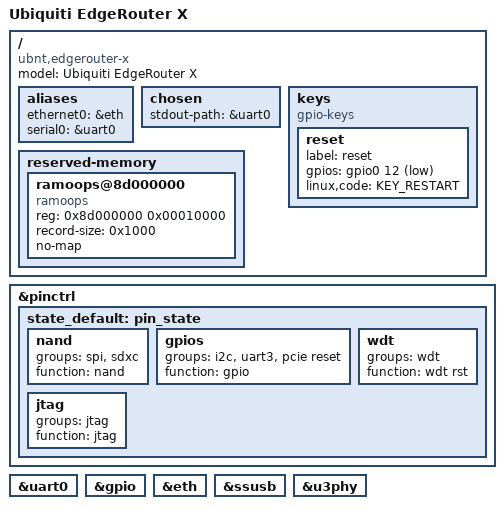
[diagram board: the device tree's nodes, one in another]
// SPDX-License-Identifier: GPL-2.0
/*
 * Copyright (C) 2024 Mauri Sandberg
 *
 */

/dts-v1/;

#include "mt7621.dtsi"
#include <dt-bindings/gpio/gpio.h>
#include <dt-bindings/input/input.h>

/ {
	compatible = "ubnt,edgerouter-x", "mediatek,mt7621-soc";
	model = "Ubiquiti EdgeRouter X";

	aliases {
		ethernet0 = &eth;
		serial0 = &uart0;
	};

	chosen {
		stdout-path = &uart0;
	};

	keys {
		compatible = "gpio-keys";

		reset {
			label = "reset";
			gpios = <&gpio0 12 GPIO_ACTIVE_LOW>;
			linux,code = <KEY_RESTART>;
		};
	};

	reserved-memory {
		#address-cells = <1>;
		#size-cells = <1>;
		ranges;

		ramoops@8d000000 {
			compatible = "ramoops";
			reg = <0x8d000000 0x00010000>;
			record-size = <0x1000>;
			no-map;
		};
	};
};

&pinctrl {
	state_default: pin_state {
		nand {
			groups = "spi", "sdxc";
			function = "nand";
		};

		gpios {
			groups = "i2c", "uart3", "pcie reset";
			function = "gpio";
		};

		wdt {
			groups = "wdt";
			function = "wdt rst";
		};

		jtag {
			groups = "jtag";
			function = "jtag";
		};
	};
};

&uart0 {
	status = "okay";
};

&gpio {
	status = "okay";
};

&eth {
	status = "okay";
};

&ssusb {
	status = "okay";
};

&u3phy {
	status = "okay";
};
